# MEC1721N_B0_LJ register map
Vendor: Microchip Technology; Series: MEC172x; File version: 0
CPU: CM4 r1p0, little endian, MPU, FPU, 3 interrupt priority bits, 172 interrupts
Registers are 32-bit, read-write, reset 0x0 unless marked. A register's access mark holds for its fields unless they carry their own. Offsets are from the block's base; [hi:lo] are bit positions; {n}, {i} and the like mark numbered series.

## ASIF — The ASIF allows the Host and EC to use index addressing to access registers residing in an external IC.
Base 0x400FC000
0x00 HOST_BAL 8-bit reset 0xE0 — LPC BAL Register
  [7:0] LPC_BAL — Nominally, the low-byte of the block's LPC base address. This register has no function. It is provided for legacy reasons.
0x01 HOST_BAH 8-bit reset 0x15 — LPC BAH Register.
  [7:0] LPC_BAH — Nominally, the high-byte of the block's LPC base address. This register has no function. It is provided for legacy reasons.
{0x2+i} SCRATCH[{i}] (i=0..9) 8-bit — Scratch 0 Register
  [7:0] SCR — This field has no functionality other than storage. This register is aliased to EC-Only Register.
0x0C HOST_AIXL 8-bit — LPC AIXL Register
  [7:0] LPC_IND_LOW — Low-byte of the 10-bit index from the LPC interface.
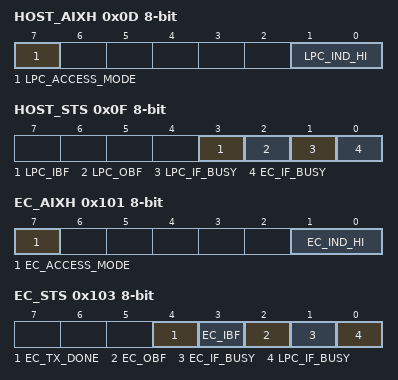
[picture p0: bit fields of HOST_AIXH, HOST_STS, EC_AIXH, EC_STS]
0x0D HOST_AIXH 8-bit — LPC AIXH Register
  [7] LPC_ACCESS_MODE — 1=Synchronous mode: the host would poll the LPC Status Register after issuing a command. When the LPC_IF_BUSY bit is cleared, write data has been latched by the external IC or read data has been fetched into the LPC Data In Register. 0=Atomic access mode. LPC cycles to Data register will be blocked until current LPC request is serviced.
  [1:0] LPC_IND_HI — Most significant two bits of the 10-bit index from the LPC interface.
0x0E HOST_DATA_IN 8-bit ro — LPC Data In Register
  [7:0] LPC_DATA_IN — This register contains data read from the external ASIC. This register shares an offset with LPC Data Out Register. After a read command is issued, software reads from this register when LPC_IF_BUSY='0' and LPC_OBF= 1.
0x0E HOST_DATA_OUT 8-bit wo — LPC Data Out Register
  [7:0] LPC_DATA_OUT — This register contains write data targeting the external ASIC. This register shares an offset with LPC Data In Register. Writes to this register are ignored while LPC_IF_BUSY is 1, i.e., until write data has been transferred to the external IC over SPI.
0x0F HOST_STS 8-bit — LPC Status Register
  [3] LPC_IBF — LPC Input Buffer Full. This bit is set to 1 after the host issues a write command. The bit is reset to 0 when the SPI write transfer to the external IC has completed.
  [2] LPC_OBF — LPC Output Buffer Full. This bit is set to 1 after read data from the external IC has been latched into the LPC Data In Register. Cleared after the ASIF returns read data to the host. This register is aliased to EC-Only Register.
  [1] LPC_IF_BUSY — LPC Interface Busy, also known as Host Command in Progress. The bit is set to 1 when the Host issues a command to the LPC interface, by either reading from the LPC Data In Register or writing to the LPC Data Out Register. The bit is cleared to 0 when the corresponding SPI transfer to the external IC is completed. This is the same bit as LPC_IF_BUSY in the EC Status Register.
  [0] EC_IF_BUSY — EC Interface Busy. Set to 1 when the EC issues a read or write to the EC_DAT Register. Set to 0 when the SPI transfer to the external ASIC that is triggered by the EC register access is completed. This is the same bit as EC_IF_BUSY in the EC Status Register.
0x100 EC_AIXL 8-bit
  [7:0] IND_LOW — Low-byte of the 10-bit index from the EC interface.
0x101 EC_AIXH 8-bit
  [7] EC_ACCESS_MODE — 0: Atomic access mode. EC cycles to Data register will be blocked until current LPC request is serviced 1: Synchronous mode: EC polls the EC Status Register after issuing a command. When EC-IF Busy bit is cleared, write data has been latched by the external IC or read data has been fetched into the EC Data In Register.
  [1:0] EC_IND_HI — Most significant two bits of the 10-bit index from the EC interface.
0x102 EC_DATA_IN 8-bit ro
  [7:0] DATA — This register contains data read from the external ASIC. This register shares an offset with EC Data Out Register. After a read command is issued, software reads from this register when EC_IF_BUSY='0' and EC_OBF= 1.
0x102 EC_DATA_OUT 8-bit wo
  [7:0] EC_DATA_OUT — This register contains write data targeting the external ASIC. This register shares an offset with EC Data In Register. Writes to this register are ignored while EC_IF_BUSY is 1, i.e., until write data has been transferred to the external IC over SPI.
0x103 EC_STS 8-bit — EC Status Register
  [4] EC_TX_DONE — EC Transmission Done. This bit is set to 1 when a write transfer to the external IC is completed. It is cleared when it is written with a 0.
  [3] EC_IBF — EC Input Buffer Full. This bit is set to 1 when the EC issues a write command to the Auxiliary SPI Interface. This bit is cleared to 0 after transfer to the external IC has completed.
  [2] EC_OBF — EC Output Buffer Full. This bit is set to 1 after read data from the external IC has been latched into the EC Data In Register. This bit is cleared to 0 after the register has been read.
  [1] EC_IF_BUSY — This bit is set to 1 when the EC issues a command to the Auxiliary SPI Interface. This bit is cleared to 0 when the corresponding SPI transfer to the external IC is completed. This bit is the same as EC_IF_BUSY in the LPC Status Register.
  [0] LPC_IF_BUSY — This bit is set to 1 when the Host issues a command to the Auxiliary SPI Interface. This bit is cleared to 0 when the corresponding SPI transfer to the external IC is completed. This bit is the same as the LPC_IF_BUSY bit in the LPC Status Register.
0x104 EC_BAL 8-bit reset 0xE0
  [7:0] LPC_BAL — Nominally, the low-byte of the block's LPC base address. This register is a writable alias of the LPC BAL Register. This register has no function. It is provided for legacy reasons.
0x105 EC_BAH 8-bit reset 0x15
  [7:0] LPC_BAH — Nominally, the high-byte of the block's LPC base address. This register is a writable alias of the LPC BAH Register. This register has no function. It is provided for legacy reasons.
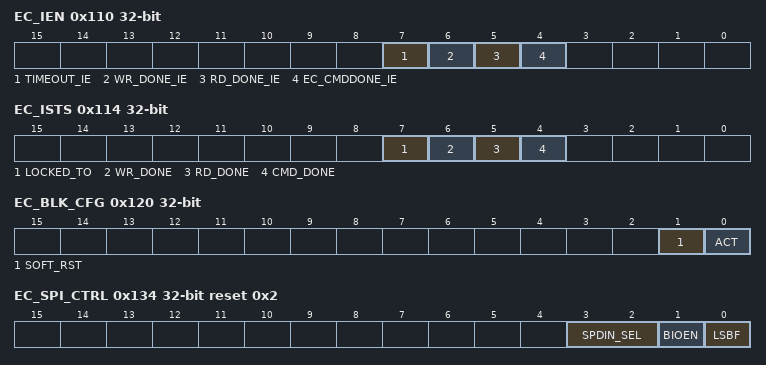
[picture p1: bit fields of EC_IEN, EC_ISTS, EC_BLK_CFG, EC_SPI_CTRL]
0x110 EC_IEN — EC Interrupt Enable Register
  [7] TIMEOUT_IE — Timeout Interrupt Enable. 1=Enable interrupt when Timeout Counter expires 0=Timeout interrupts disabled.
  [6] WR_DONE_IE — Write Done Interrupt Enable. 1=Enable interrupt when transfer of write data to the external IC is complete (when the status bit EC_WR_DONE is 1) 0=Write Done interrupts disabled.
  [5] RD_DONE_IE — Read Done Interrupt Enable. 1=Enable interrupt when read data from the external IC is available for the EC (when the status bit EC_RD_DONE is 1) 0=Read Done interrupts disabled
  [4] EC_CMDDONE_IE — EC Command Done Interrupt Enable. 1=Enable interrupt when the transaction to the external IC is complete (when the status bit EC_CMD_DONE is 1) 0=Command Done interrupts disabled.
0x114 EC_ISTS — EC Interrupt Status Register
  [7] LOCKED_TO — Locked Timeout. This bit is set to 1 when the Timeout Counter Register counts down to 0, indicating the Auxiliary Serial Interface is reset due to a time-out event. Although this bit is cleared to 0 on a Soft Reset that is generated by a write to the SOFT_RESET bit, it is not cleared if the Soft Reset is generated by a time-out event. This bit is cleared when written with a 1. Writes of a 0 have no effect.
  [6] WR_DONE — Write Done Status.This bit is set to 1 when EC write data has been transfered to the external IC (when EC_IF_BUSY is cleared). This bit is cleared when written with a 1. Writes of a 0 have no effect.
  [5] RD_DONE — Read Done Status.This bit is set to 1 when the external IC returns data to the EC as a result of an EC read command. This bit is cleared when written with a 1. Writes of a 0 have no effect.
  [4] CMD_DONE — EC Command Done Status. This bit is set to 1 when the SPI transfer to service an EC command to the external IC, either read or write, has completed. This bit is cleared when written with a 1. Writes of a 0 have no effect.
0x118 EC_TMOUT_CNTR reset 0xFF — Timeout Counter Register.
  [7:0] TIMEOUT_CNT — Timeout period in number of 100KHz cycles -1. Reads return the current count value.
0x120 EC_BLK_CFG — Block Configuration Register
  [1] SOFT_RST — Set to 1 to issue a soft reset to the block. Soft reset has similar effect as a hardware power-on reset except that register settings other than status bits remain unchanged. This bit is self-clearing. The interface bus signals after a soft reset are as follows: SPI_CS# is de-asserted high; SPI clock is low; SPI_MOSI is high after POR and retains its bus value when Soft Reset is asserted; SPI_MISO is input.
  [0] ACT — 1=Block is operational 0=Block is disabled. Clocks are gated to conserve power and output signals are set to their inactive state. The block must finish all outstanding transactions on both SPI and LPC/EC logical interfaces before it can gate off internal clocks.
0x130 EC_SPI_CLK_GEN reset 0x7 — SPI Clock Generator Register.
  [5:0] PRELD — SPI Clock Generator Preload value.
0x134 EC_SPI_CTRL reset 0x2 — SPI Control Register
  [3:2] SPDIN_SEL — The SPDIN Select which SPI input signals are enabled when the BIOEN bit is configured as an input. 1xb=SPDIN1 and SPDIN2. Select this option for Dual Mode 01b=SPDIN2 only. Select this option for Half Duplex 00b=SPDIN1 only. Select this option for Full Duplex.
  [1] BIOEN — Bidirectional Output Enable control. When the SPI is configured for Half Duplex mode or Dual Mode the SPDOUT pin operates as a bidirectional signal. The BIOEN bit is used by the internal DIRECTION bit to control the direction of the SPDOUT buffers. The direction of the buffer is never changed while a byte is being transmitted. 1=The SPDOUT_Direction signal configures the SPDOUT signal as an output. 0=The SPDOUT_Direction signal configures the SPDOUT signal as an input. If the SPIMODE bit is configured for Full Duplex mode the BIOEN bit must be set to 1 to configure the SPI_MOSI signal as an output. Although the design supports back-to-back transmissions even when the direction of the buffer is changed, it is the software's responsibility to avoid collisions on the SPI_MOSI signal. The design has been implemented to support a 0 second (max) turnaround (TAR) time. If TAR greater than zero is required, the software must wait for the transmission in one direction to complete before writing the TX_DATA register to start sending/receiving in the opposite direction.
  [0] LSBF — Least Significant Bit First. 1= The data is transferred in LSB-first order. 0= The data is transferred in MSB-first order. (default).
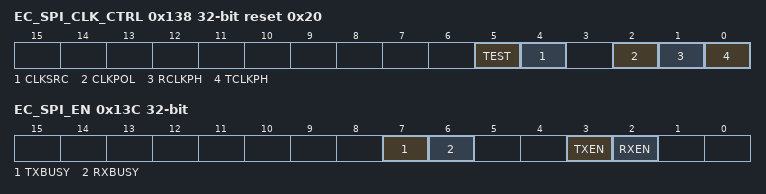
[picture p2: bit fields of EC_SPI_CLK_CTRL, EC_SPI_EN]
0x138 EC_SPI_CLK_CTRL reset 0x20 — SPI Clock Control Register
  [5] TEST — This bit must remain at 1, its reset default, for correct operation.
  [4] CLKSRC — Clock Source for the SPI Clock Generator. This bit should not be changed during a SPI transaction. When the field PRELOAD in the SPI Clock Generator Register is 0, this bit is ignored and the Clock Source is always the main system clock (the equivalent of setting this bit to 0). 1=2MHz; 0=48MHz.
  [2] CLKPOL — SPI Clock Polarity. 1=The SPI_CLK signal is high when the interface is idle and the first clock edge is a falling edge 0=The SPI_CLK is low when the interface is idle and the first clock edge is a rising edge.
  [1] RCLKPH — Receive Clock Phase, the SPI_CLK edge on which the master will sample data. The receive clock phase is not affected by the SPI Clock Polarity. 1=Valid data on SPDIN signal is expected after the first SPI_CLK edge. This data is sampled on the second and following even SPI_CLK edges (i.e., sample data on falling edge) 0=Valid data is expected on the SPDIN signal on the first SPI_CLK edge. This data is sampled on the first and following odd SPI_CLK edges (i.e., sample data on rising edge)
  [0] TCLKPH — Transmit Clock Phase, the SPCLK edge on which the master will clock data out. The transmit clock phase is not affected by the SPI Clock Polarity. 1=Valid data is clocked out on the first SPI_CLK edge on SPDOUT signal. The slave device should sample this data on the second and following even SPI_CLK edges (i.e., sample data on falling edge) 0=Valid data is clocked out on the SPDOUT signal prior to the first SPI_CLK edge. The slave device should sample this data on the first and following odd SPI_CLK edges (i.e., sample data on rising edge).
0x13C EC_SPI_EN — SPI Enable Register
  [7] TXBUSY — Transmit Busy. 1=Set when a SPI write transfer to external IC is started. Cleared when the transfer is completed 0=Transmit channel idle.
  [6] RXBUSY — Receive Busy. 1=Set when a SPI read transfer to external IC is started. Cleared when the transfer is completed 0=Receive channel idle.
  [3] TXEN — SPI Transmit transfer enable. 1=SPI write transfer is enabled 0=SPI write transfer is disabled. Write commands received at the LPC and EC interfaces will not result in SPI transfers to IC, i.e., address and write data are not shifted out.
  [2] RXEN — SPI Receive transfer enable. 1=SPI read transfer is enabled 0=SPI read transfer is disabled. Read commands received at the LPC and EC interfaces will not result in SPI transfers to IC, i.e., address is not shifted out and read data not shifted in.
